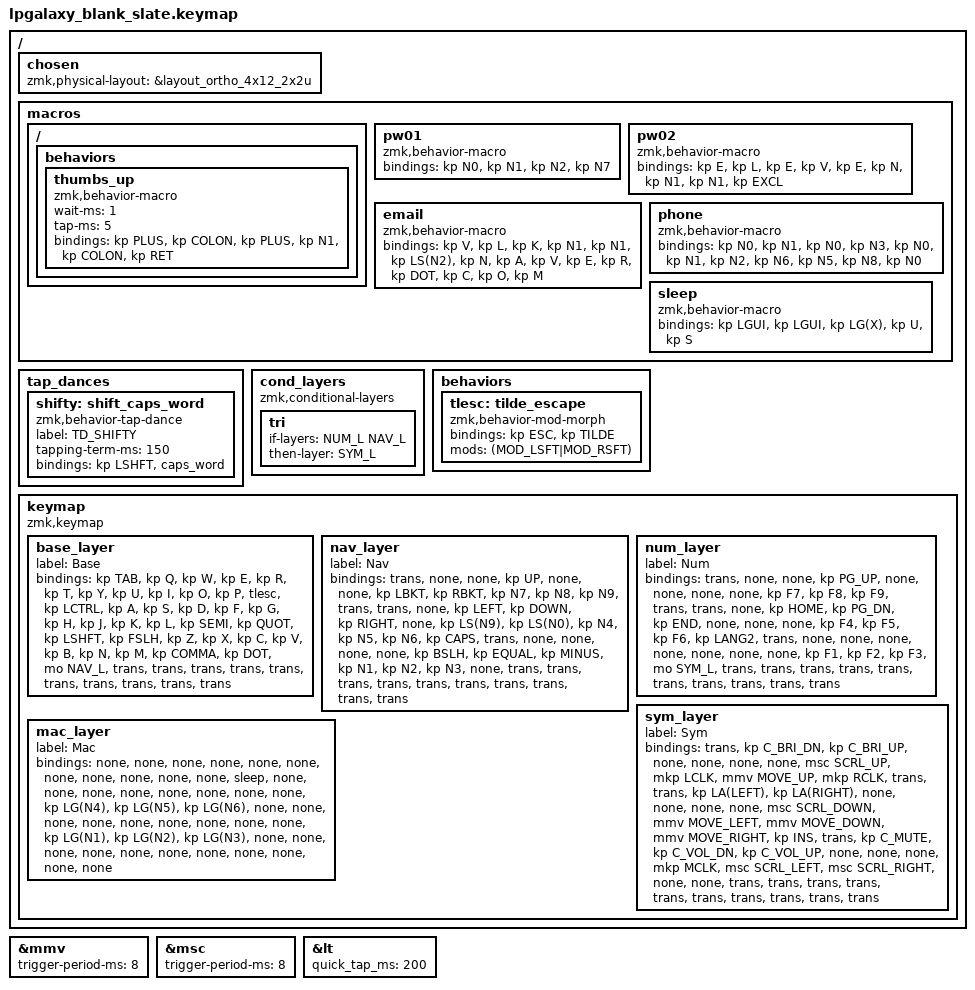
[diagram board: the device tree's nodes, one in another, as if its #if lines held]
/*
 * Copyright (c) 2022 Pete Johanson
 *
 * SPDX-License-Identifier: MIT
 */

#include <behaviors.dtsi>
#include <dt-bindings/zmk/keys.h>
#include <dt-bindings/zmk/bt.h>
#include <dt-bindings/zmk/outputs.h>

#include <dt-bindings/zmk/pointing.h>
#define ZMK_POINTING_DEFAULT_MOVE_VAL 1000
#define ZMK_POINTING_DEFAULT_SCRL_VAL 20

&mmv {
	trigger-period-ms = <8>;
};

&msc {
	trigger-period-ms = <8>;
};

#define QWERTY_BASE 1

#define TBLE_ORTHO   1
// #define TBLE_MIT     1
// #define TBLE_DUAL_2U 1

#define NAV_L 1
#define NUM_L 2
#define SYM_L 3
#define MAC_L 4
#define EXTRA 5

// Using layer taps on thumbs, having quick tap as well helps w/ repeating space/backspace
&lt { quick_tap_ms = <200>; };

#define BT(n) BT_SEL n



/ {

    chosen {
       zmk,physical-layout =
#ifdef TBLE_DUAL_2U
                       &layout_ortho_4x12_2x2u;
#elif defined(TBLE_MIT)
                       &layout_ortho_4x12_1x2u;
#else
                       &layout_ortho_4x12_all1u;
#endif
    };



    macros {

      ZMK_MACRO(thumbs_up,
		wait-ms = <1>;
		tap-ms = <5>;
                bindings = <&kp PLUS &kp COLON &kp PLUS &kp N1 &kp COLON &kp RET>;
		)

      pw01: pw01 { // 0127
		compatible = "zmk,behavior-macro";
		#binding-cells = <0>;
		bindings
                = <&kp N0>
		, <&kp N1>
		, <&kp N2>
		, <&kp N7>
		;
		};      

      pw02: pw02 { // eleven11!
		compatible = "zmk,behavior-macro";
		#binding-cells = <0>;
		bindings
                = <&kp E>
		, <&kp L>
		, <&kp E>	
		, <&kp V>
		, <&kp E>
		, <&kp N>
		, <&kp N1>
		, <&kp N1>
		, <&kp EXCL>
		;
		};

      email: email { // vlk11@naver.com
		compatible = "zmk,behavior-macro";
		#binding-cells = <0>;
		bindings
                = <&kp V>
		, <&kp L>
		, <&kp K>	
		, <&kp N1>
		, <&kp N1>
		, <&kp LS(N2)>
		, <&kp N>
		, <&kp A>
		, <&kp V>
		, <&kp E>
		, <&kp R>
		, <&kp DOT>
		, <&kp C>
		, <&kp O>
		, <&kp M>
		;
		};

      phone: phone { // 01030126580
		compatible = "zmk,behavior-macro";
		#binding-cells = <0>;
		bindings
                = <&kp N0>
		, <&kp N1>
		, <&kp N0>	
		, <&kp N3>
		, <&kp N0>
		, <&kp N1>
		, <&kp N2>
		, <&kp N6>
		, <&kp N5>
		, <&kp N8>
		, <&kp N0>
		;
		};

      sleep: sleep {
		compatible = "zmk,behavior-macro";
		#binding-cells = <0>;
		bindings
		= <&kp LGUI>
		, <&kp LGUI>
		, <&kp LG(X)>
		, <&kp U>
		, <&kp S>
		;
		};
    };



    tap_dances {
    	shifty: shift_caps_word {
		compatible = "zmk,behavior-tap-dance";
		label = "TD_SHIFTY";
		#binding-cells = <0>;
		tapping-term-ms = <150>;
		bindings = <&kp LSHFT>, <&caps_word>;
	};
    };



// Conditional layer only when we have less thumb keys
#ifdef TBLE_DUAL_2U
    cond_layers {
        compatible = "zmk,conditional-layers";
	tri {
	    if-layers = <NUM_L NAV_L>;
	    then-layer = <SYM_L>;
        };
    };
#endif

    behaviors {
        tlesc: tilde_escape {
            compatible = "zmk,behavior-mod-morph";
            #binding-cells = <0>;
            bindings = <&kp ESC>, <&kp TILDE>;
            mods = <(MOD_LSFT|MOD_RSFT)>;
        };
    };



    keymap {
        compatible = "zmk,keymap";

        base_layer {
            label = "Base";
            bindings = <
#ifdef QWERTY_BASE
	&kp TAB		&kp Q		&kp W		&kp E		&kp R		&kp T		&kp Y		&kp U		&kp I		&kp O		&kp P		&tlesc
	&kp LCTRL	&kp A		&kp S		&kp D		&kp F		&kp G		&kp H		&kp J		&kp K		&kp L		&kp SEMI	&kp QUOT
	&kp LSHFT	&kp FSLH	&kp Z		&kp X		&kp C		&kp V		&kp B		&kp N		&kp M		&kp COMMA	&kp DOT		&mo NAV_L
#else
	&kp TAB		&kp Q		&kp W		&kp E		&kp R		&kp T		&kp Y		&kp U		&kp I		&kp O		&kp P		&tlesc
	&kp LCTRL	&kp A		&kp S		&kp D		&kp F		&kp G		&kp H		&kp J		&kp K		&kp L		&kp SEMI	&kp QUOT
	&kp LSHFT	&kp FSLH	&kp Z		&kp X		&kp C		&kp V		&kp B		&kp N		&kp M		&kp COMMA	&kp DOT		&mo NAV_L
#endif
#ifdef TBLE_DUAL_2U
	&trans		&trans		&trans		&trans		        &trans		    	        &trans			&trans		&trans		&trans		&trans
#elif defined(TBLE_MIT)
	&trans		&trans		&trans		&trans		&trans		       &trans			&trans		&trans		&trans		&trans		&trans
#else
	&kp LALT	&kp LGUI	&mo NUM_L	&mo NAV_L	&kp ENTER	&kp SPACE	&kp BSPC	&kp DEL		&mo MAC_L	&kp K_APP	&kp LANG1	&mo NUM_L
#endif
            >;
        };

        nav_layer {
            label = "Nav";
            bindings = <
	&trans		&none		&none		&kp UP		&none		&none		&kp LBKT	&kp RBKT	&kp N7		&kp N8		&kp N9		&trans
	&trans		&none		&kp LEFT	&kp DOWN	&kp RIGHT	&none		&kp LS(N9)	&kp LS(N0)	&kp N4		&kp N5		&kp N6		&kp CAPS
	&trans		&none		&none		&none		&none		&kp BSLH	&kp EQUAL	&kp MINUS	&kp N1		&kp N2		&kp N3		&none
#ifdef TBLE_DUAL_2U
	&trans		&trans		&trans		&trans		        &trans		    	        &trans			&trans		&trans		&trans		&trans
#elif defined(TBLE_MIT)
	&trans		&trans		&trans		&trans		&trans		       &trans			&trans		&trans		&trans		&trans		&trans
#else
	&trans		&trans		&mo SYM_L	&none		&trans		&trans		&trans		&trans		&kp N0		&kp DOT		&kp COMMA	&mo SYM_L
#endif
            >;
        };

        num_layer {
            label = "Num";
            bindings = <
	&trans		&none		&none		&kp PG_UP	&none		&none		&none		&none		&kp F7		&kp F8		&kp F9		&trans
	&trans		&none		&kp HOME	&kp PG_DN	&kp END		&none		&none		&none		&kp F4		&kp F5		&kp F6		&kp LANG2
	&trans		&none		&none		&none		&none		&none		&none		&none		&kp F1		&kp F2		&kp F3		&mo SYM_L
#ifdef TBLE_DUAL_2U
	&trans		&trans		&trans		&trans		        &trans		    	        &trans			&trans		&trans		&trans		&trans
#elif defined(TBLE_MIT)
	&trans		&trans		&trans		&trans		&trans		       &trans			&trans		&trans		&trans		&trans		&trans
#else
	&trans		&trans		&none		&mo SYM_L	&trans		&trans		&trans		&trans		&kp F10		&kp F11		&kp F12		&none
#endif
            >;
        };

        sym_layer {
            label = "Sym";
            bindings = <
	&trans		&kp C_BRI_DN	&kp C_BRI_UP	&none		&none		&none		&none		&msc SCRL_UP	&mkp LCLK	&mmv MOVE_UP	&mkp RCLK	&trans
	&trans		&kp LA(LEFT)	&kp LA(RIGHT)	&none		&none		&none		&none		&msc SCRL_DOWN	&mmv MOVE_LEFT	&mmv MOVE_DOWN	&mmv MOVE_RIGHT	&kp INS
	&trans		&kp C_MUTE	&kp C_VOL_DN	&kp C_VOL_UP	&none		&none		&none		&mkp MCLK	&msc SCRL_LEFT	&msc SCRL_RIGHT	&none		&none
#ifdef TBLE_DUAL_2U
	&trans		&trans		&trans		&trans		        &trans		    	        &trans			&trans		&trans		&trans		&trans
#elif defined(TBLE_MIT)
	&trans		&trans		&trans		&trans		&trans		       &trans			&trans		&trans		&trans		&trans		&trans
#else
	&trans		&trans		&none		&none		&trans		&trans		&trans		&trans		&none		&none		&none		&none
#endif
            >;
        };

        mac_layer {
            label = "Mac";
            bindings = <
	&none		&none		&none		&none		&none		&none		&none		&none		&none		&none		&none		&sleep
	&none		&none		&none		&none		&none		&none		&none		&none		&kp LG(N4)	&kp LG(N5)	&kp LG(N6)	&none
	&none		&none		&none		&none		&none		&none		&none		&none		&kp LG(N1)	&kp LG(N2)	&kp LG(N3)	&none
#ifdef TBLE_DUAL_2U
	&none		&none		&none		&none		        &none		                &none			&none		&none		&none		&none
#elif defined(TBLE_MIT)
	&none		&none		&none		&none		&none		        &none			&none		&none		&none		&none		&none
#else
	&none		&email		&phone		&none		&none		&none		&kp LA(F4)	&none		&none		&pw01		&pw02		&none
#endif
            >;
        };

    };
};

